AUTOSAR XML (schema 00044)
package /VAG/Services/BAP
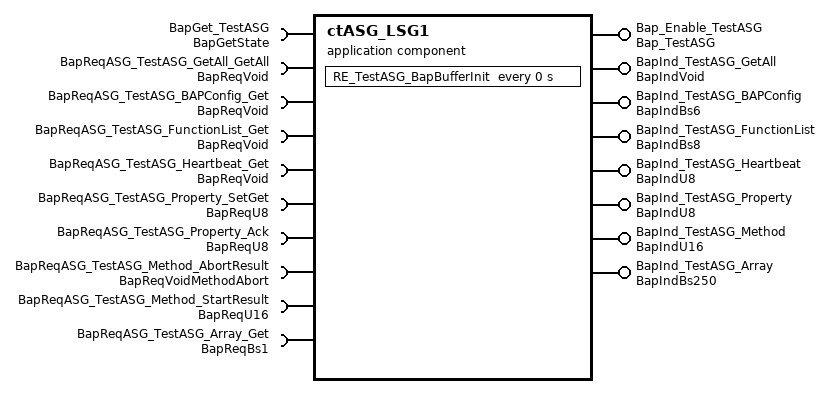
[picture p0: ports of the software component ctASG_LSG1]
  application sw component type ctASG_LSG1
    require port BapGet_TestASG: client-com-spec=State, required-interface=BapGetState
    provide port Bap_Enable_TestASG: nonqueued-sender-com-spec{data-element=BapEnable, init-value=constant-reference=C_Bool_FALSE}, provided-interface=Bap_TestASG
    provide port BapInd_TestASG_GetAll: provided-interface=BapIndVoid
      provided-com-specs:
        operation=BAP_IndVoid, queue-length=1
        operation=BAP_IndError, queue-length=1
        operation=BAP_Ack, queue-length=1
    require port BapReqASG_TestASG_GetAll_GetAll: client-com-spec=BAP_ReqVoid, required-interface=BapReqVoid
    provide port BapInd_TestASG_BAPConfig: provided-interface=BapIndBs6
      provided-com-specs:
        operation=BAP_IndBs, queue-length=1
        operation=BAP_IndError, queue-length=1
        operation=BAP_Ack, queue-length=1
    require port BapReqASG_TestASG_BAPConfig_Get: client-com-spec=BAP_ReqVoid, required-interface=BapReqVoid
    provide port BapInd_TestASG_FunctionList: provided-interface=BapIndBs8
      provided-com-specs:
        operation=BAP_IndBs, queue-length=1
        operation=BAP_IndError, queue-length=1
        operation=BAP_Ack, queue-length=1
    require port BapReqASG_TestASG_FunctionList_Get: client-com-spec=BAP_ReqVoid, required-interface=BapReqVoid
    provide port BapInd_TestASG_Heartbeat: provided-interface=BapIndU8
      provided-com-specs:
        operation=BAP_IndU8, queue-length=1
        operation=BAP_IndError, queue-length=1
        operation=BAP_Ack, queue-length=1
    require port BapReqASG_TestASG_Heartbeat_Get: client-com-spec=BAP_ReqVoid, required-interface=BapReqVoid
    provide port BapInd_TestASG_Property: provided-interface=BapIndU8
      provided-com-specs:
        operation=BAP_IndU8, queue-length=1
        operation=BAP_IndError, queue-length=1
        operation=BAP_Ack, queue-length=1
    require port BapReqASG_TestASG_Property_SetGet: client-com-spec=BAP_ReqU8, required-interface=BapReqU8
    require port BapReqASG_TestASG_Property_Ack: client-com-spec=BAP_ReqU8, required-interface=BapReqU8
    provide port BapInd_TestASG_Method: provided-interface=BapIndU16
      provided-com-specs:
        operation=BAP_IndU16, queue-length=1
        operation=BAP_IndError, queue-length=1
        operation=BAP_Ack, queue-length=1
    require port BapReqASG_TestASG_Method_AbortResult: client-com-spec=BAP_ReqVoid, required-interface=BapReqVoidMethodAbort
    require port BapReqASG_TestASG_Method_StartResult: client-com-spec=BAP_ReqU16, required-interface=BapReqU16
    provide port BapInd_TestASG_Array: provided-interface=BapIndBs250
      provided-com-specs:
        operation=BAP_IndBs, queue-length=1
        operation=BAP_IndError, queue-length=1
        operation=BAP_Ack, queue-length=1
    require port BapReqASG_TestASG_Array_Get: client-com-spec=BAP_ReqBs, required-interface=BapReqBs1
    behavior IB_ctASG_LSG1
      timing event TE_RE_TestASG_BapBufferInit: start-on-event=RE_TestASG_BapBufferInit, period=0
      21 x operation invoked event:
        OIE_RE_TestASG_BAPIndVoid_GetAll_BapInd_TestASG_GetAll: start-on-event=RE_TestASG_BAPIndVoid_GetAll, operation=BapInd_TestASG_GetAll.BAP_IndVoid
        OIE_RE_TestASG_BAPIndError_GetAll_BapInd_TestASG_GetAll: start-on-event=RE_TestASG_BAPIndError_GetAll, operation=BapInd_TestASG_GetAll.BAP_IndError
        OIE_RE_TestASG_BAPAck_GetAll_BapInd_TestASG_GetAll: start-on-event=RE_TestASG_BAPAck_GetAll, operation=BapInd_TestASG_GetAll.BAP_Ack
        OIE_RE_TestASG_BAPIndBs_BAPConfig_BapInd_TestASG_BAPConfig: start-on-event=RE_TestASG_BAPIndBs_BAPConfig, operation=BapInd_TestASG_BAPConfig.BAP_IndBs
        OIE_RE_TestASG_BAPIndError_BAPConfig_BapInd_TestASG_BAPConfig: start-on-event=RE_TestASG_BAPIndError_BAPConfig, operation=BapInd_TestASG_BAPConfig.BAP_IndError
        OIE_RE_TestASG_BAPAck_BAPConfig_BapInd_TestASG_BAPConfig: start-on-event=RE_TestASG_BAPAck_BAPConfig, operation=BapInd_TestASG_BAPConfig.BAP_Ack
        OIE_RE_TestASG_BAPIndBs_FunctionList_BapInd_TestASG_FunctionList: start-on-event=RE_TestASG_BAPIndBs_FunctionList, operation=BapInd_TestASG_FunctionList.BAP_IndBs
        OIE_RE_TestASG_BAPIndError_FunctionList_BapInd_TestASG_FunctionList: start-on-event=RE_TestASG_BAPIndError_FunctionList, operation=BapInd_TestASG_FunctionList.BAP_IndError
        OIE_RE_TestASG_BAPAck_FunctionList_BapInd_TestASG_FunctionList: start-on-event=RE_TestASG_BAPAck_FunctionList, operation=BapInd_TestASG_FunctionList.BAP_Ack
        OIE_RE_TestASG_BAPIndU8_Heartbeat_BapInd_TestASG_Heartbeat: start-on-event=RE_TestASG_BAPIndU8_Heartbeat, operation=BapInd_TestASG_Heartbeat.BAP_IndU8
        OIE_RE_TestASG_BAPIndError_Heartbeat_BapInd_TestASG_Heartbeat: start-on-event=RE_TestASG_BAPIndError_Heartbeat, operation=BapInd_TestASG_Heartbeat.BAP_IndError
        OIE_RE_TestASG_BAPAck_Heartbeat_BapInd_TestASG_Heartbeat: start-on-event=RE_TestASG_BAPAck_Heartbeat, operation=BapInd_TestASG_Heartbeat.BAP_Ack
        OIE_RE_TestASG_BAPIndU8_Property_BapInd_TestASG_Property: start-on-event=RE_TestASG_BAPIndU8_Property, operation=BapInd_TestASG_Property.BAP_IndU8
        OIE_RE_TestASG_BAPIndError_Property_BapInd_TestASG_Property: start-on-event=RE_TestASG_BAPIndError_Property, operation=BapInd_TestASG_Property.BAP_IndError
        OIE_RE_TestASG_BAPAck_Property_BapInd_TestASG_Property: start-on-event=RE_TestASG_BAPAck_Property, operation=BapInd_TestASG_Property.BAP_Ack
        OIE_RE_TestASG_BAPIndU16_Method_BapInd_TestASG_Method: start-on-event=RE_TestASG_BAPIndU16_Method, operation=BapInd_TestASG_Method.BAP_IndU16
        OIE_RE_TestASG_BAPIndError_Method_BapInd_TestASG_Method: start-on-event=RE_TestASG_BAPIndError_Method, operation=BapInd_TestASG_Method.BAP_IndError
        OIE_RE_TestASG_BAPAck_Method_BapInd_TestASG_Method: start-on-event=RE_TestASG_BAPAck_Method, operation=BapInd_TestASG_Method.BAP_Ack
        OIE_RE_TestASG_BAPIndBs_Array_BapInd_TestASG_Array: start-on-event=RE_TestASG_BAPIndBs_Array, operation=BapInd_TestASG_Array.BAP_IndBs
        OIE_RE_TestASG_BAPIndError_Array_BapInd_TestASG_Array: start-on-event=RE_TestASG_BAPIndError_Array, operation=BapInd_TestASG_Array.BAP_IndError
        OIE_RE_TestASG_BAPAck_Array_BapInd_TestASG_Array: start-on-event=RE_TestASG_BAPAck_Array, operation=BapInd_TestASG_Array.BAP_Ack
      port-api-options:
        enable-take-address=false, indirect-api=false, port=BapGet_TestASG
        enable-take-address=false, indirect-api=false, port=BapReqASG_TestASG_GetAll_GetAll
        enable-take-address=false, indirect-api=false, port=BapReqASG_TestASG_BAPConfig_Get
        enable-take-address=false, indirect-api=false, port=BapReqASG_TestASG_FunctionList_Get
        enable-take-address=false, indirect-api=false, port=BapReqASG_TestASG_Heartbeat_Get
        enable-take-address=false, indirect-api=false, port=BapReqASG_TestASG_Property_SetGet
        enable-take-address=false, indirect-api=false, port=BapReqASG_TestASG_Property_Ack
        enable-take-address=false, indirect-api=false, port=BapReqASG_TestASG_Method_AbortResult
        enable-take-address=false, indirect-api=false, port=BapReqASG_TestASG_Method_StartResult
        enable-take-address=false, indirect-api=false, port=BapReqASG_TestASG_Array_Get
        enable-take-address=false, indirect-api=false, port=Bap_Enable_TestASG
        enable-take-address=false, indirect-api=false, port=BapInd_TestASG_GetAll
        enable-take-address=false, indirect-api=false, port=BapInd_TestASG_BAPConfig
        enable-take-address=false, indirect-api=false, port=BapInd_TestASG_FunctionList
        enable-take-address=false, indirect-api=false, port=BapInd_TestASG_Heartbeat
        enable-take-address=false, indirect-api=false, port=BapInd_TestASG_Property
        enable-take-address=false, indirect-api=false, port=BapInd_TestASG_Method
        enable-take-address=false, indirect-api=false, port=BapInd_TestASG_Array
      22 x runnable:
        RE_TestASG_BapBufferInit: symbol=BAP_ASR_TestASG_BapBufferInit
          data-send-points:
            access DSP_Bap_Enable_TestASG_BapEnable: accessed-variable=Bap_Enable_TestASG.BapEnable
          10 x sync call:
            SCP_BapGet_TestASG_State: operation=BapGet_TestASG.State
            SCP_BapReqASG_TestASG_GetAll_GetAll_BAP_ReqVoid: operation=BapReqASG_TestASG_GetAll_GetAll.BAP_ReqVoid
            SCP_BapReqASG_TestASG_BAPConfig_Get_BAP_ReqVoid: operation=BapReqASG_TestASG_BAPConfig_Get.BAP_ReqVoid
            SCP_BapReqASG_TestASG_FunctionList_Get_BAP_ReqVoid: operation=BapReqASG_TestASG_FunctionList_Get.BAP_ReqVoid
            SCP_BapReqASG_TestASG_Heartbeat_Get_BAP_ReqVoid: operation=BapReqASG_TestASG_Heartbeat_Get.BAP_ReqVoid
            SCP_BapReqASG_TestASG_Property_SetGet_BAP_ReqU8: operation=BapReqASG_TestASG_Property_SetGet.BAP_ReqU8
            SCP_BapReqASG_TestASG_Property_Ack_BAP_ReqU8: operation=BapReqASG_TestASG_Property_Ack.BAP_ReqU8
            SCP_BapReqASG_TestASG_Method_AbortResult_BAP_ReqVoid: operation=BapReqASG_TestASG_Method_AbortResult.BAP_ReqVoid
            SCP_BapReqASG_TestASG_Method_StartResult_BAP_ReqU16: operation=BapReqASG_TestASG_Method_StartResult.BAP_ReqU16
            SCP_BapReqASG_TestASG_Array_Get_BAP_ReqBs: operation=BapReqASG_TestASG_Array_Get.BAP_ReqBs
        RE_TestASG_BAPIndVoid_GetAll: can-be-invoked-concurrently=true, symbol=BAP_ASR_TestASG_BAPIndVoid_GetAll
        RE_TestASG_BAPIndError_GetAll: can-be-invoked-concurrently=true, symbol=BAP_ASR_TestASG_BAPIndError_GetAll
        RE_TestASG_BAPAck_GetAll: can-be-invoked-concurrently=true, symbol=BAP_ASR_TestASG_BAPAck_GetAll
        RE_TestASG_BAPIndBs_BAPConfig: can-be-invoked-concurrently=true, symbol=BAP_ASR_TestASG_BAPIndBs_BAPConfig
        RE_TestASG_BAPIndError_BAPConfig: can-be-invoked-concurrently=true, symbol=BAP_ASR_TestASG_BAPIndError_BAPConfig
        RE_TestASG_BAPAck_BAPConfig: can-be-invoked-concurrently=true, symbol=BAP_ASR_TestASG_BAPAck_BAPConfig
        RE_TestASG_BAPIndBs_FunctionList: can-be-invoked-concurrently=true, symbol=BAP_ASR_TestASG_BAPIndBs_FunctionList
        RE_TestASG_BAPIndError_FunctionList: can-be-invoked-concurrently=true, symbol=BAP_ASR_TestASG_BAPIndError_FunctionList
        RE_TestASG_BAPAck_FunctionList: can-be-invoked-concurrently=true, symbol=BAP_ASR_TestASG_BAPAck_FunctionList
        RE_TestASG_BAPIndU8_Heartbeat: can-be-invoked-concurrently=true, symbol=BAP_ASR_TestASG_BAPIndU8_Heartbeat
        RE_TestASG_BAPIndError_Heartbeat: can-be-invoked-concurrently=true, symbol=BAP_ASR_TestASG_BAPIndError_Heartbeat
        RE_TestASG_BAPAck_Heartbeat: can-be-invoked-concurrently=true, symbol=BAP_ASR_TestASG_BAPAck_Heartbeat
        RE_TestASG_BAPIndU8_Property: can-be-invoked-concurrently=true, symbol=BAP_ASR_TestASG_BAPIndU8_Property
        RE_TestASG_BAPIndError_Property: can-be-invoked-concurrently=true, symbol=BAP_ASR_TestASG_BAPIndError_Property
        RE_TestASG_BAPAck_Property: can-be-invoked-concurrently=true, symbol=BAP_ASR_TestASG_BAPAck_Property
        RE_TestASG_BAPIndU16_Method: can-be-invoked-concurrently=true, symbol=BAP_ASR_TestASG_BAPIndU16_Method
        RE_TestASG_BAPIndError_Method: can-be-invoked-concurrently=true, symbol=BAP_ASR_TestASG_BAPIndError_Method
        RE_TestASG_BAPAck_Method: can-be-invoked-concurrently=true, symbol=BAP_ASR_TestASG_BAPAck_Method
        RE_TestASG_BAPIndBs_Array: can-be-invoked-concurrently=true, symbol=BAP_ASR_TestASG_BAPIndBs_Array
        RE_TestASG_BAPIndError_Array: can-be-invoked-concurrently=true, symbol=BAP_ASR_TestASG_BAPIndError_Array
        RE_TestASG_BAPAck_Array: can-be-invoked-concurrently=true, symbol=BAP_ASR_TestASG_BAPAck_Array
